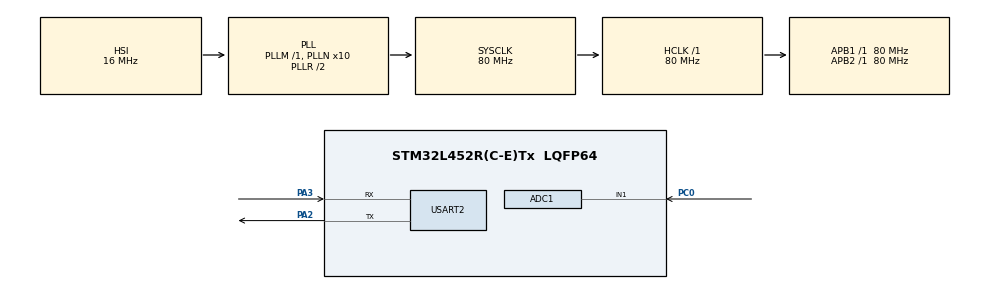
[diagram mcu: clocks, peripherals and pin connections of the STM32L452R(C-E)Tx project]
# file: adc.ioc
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ADC1.Channel-0\#ChannelRegularConversion=ADC_CHANNEL_1
ADC1.NbrOfConversionFlag=1
ADC1.OffsetNumber-0\#ChannelRegularConversion=ADC_OFFSET_NONE
ADC1.Rank-0\#ChannelRegularConversion=1
ADC1.SamplingTime-0\#ChannelRegularConversion=ADC_SAMPLETIME_2CYCLES_5
ADC1.master=1
Mcu.Family=STM32L4
Mcu.Name=STM32L452R(C-E)Tx
Mcu.Package=LQFP64
NVIC.PriorityGroup=NVIC_PRIORITYGROUP_4
PA2.Mode=Asynchronous
PA2.Signal=USART2_TX
PA3.Mode=Asynchronous
PA3.Signal=USART2_RX
PC0.Signal=ADCx_IN1
ProjectManager.HeapSize=0x200
ProjectManager.StackSize=0x400
ProjectManager.TargetToolchain=STM32CubeIDE
RCC.ADCFreq_Value=64000000
RCC.AHBFreq_Value=80000000
RCC.APB1Freq_Value=80000000
RCC.APB1TimFreq_Value=80000000
RCC.APB2Freq_Value=80000000
RCC.APB2TimFreq_Value=80000000
RCC.CortexFreq_Value=80000000
RCC.HCLKFreq_Value=80000000
RCC.HSE_VALUE=8000000
RCC.HSI48_VALUE=48000000
RCC.HSI_VALUE=16000000
RCC.MSI_VALUE=4000000
RCC.PLLN=10
RCC.PLLSourceVirtual=RCC_PLLSOURCE_HSI
RCC.PREFETCH_ENABLE=1
RCC.SYSCLKFreq_VALUE=80000000
RCC.SYSCLKSource=RCC_SYSCLKSOURCE_PLLCLK
RCC.USBFreq_Value=64000000
RCC.VCOOutputFreq_Value=160000000
SH.ADCx_IN1.0=ADC1_IN1,IN1-Single-Ended
USART2.VirtualMode-Asynchronous=VM_ASYNC
board=NUCLEO-L452RE

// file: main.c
/* USER CODE BEGIN Header */
/**
  ******************************************************************************
  * @file           : main.c
  * @brief          : Main program body
  ******************************************************************************
  * @attention
  *
  * Copyright (c) 2024 STMicroelectronics.
  * All rights reserved.
  *
  * This software is licensed under terms that can be found in the LICENSE file
  * in the root directory of this software component.
  * If no LICENSE file comes with this software, it is provided AS-IS.
  *
  ******************************************************************************
  */
/* USER CODE END Header */
#include "main.h"

ADC_HandleTypeDef hadc1;

UART_HandleTypeDef huart2;

void SystemClock_Config(void);
static void MX_GPIO_Init(void);
static void MX_ADC1_Init(void);
static void MX_USART2_UART_Init(void);

int main(void)
{

  /* MCU Configuration--------------------------------------------------------*/

  /* Reset of all peripherals, Initializes the Flash interface and the Systick. */
  HAL_Init();

  /* Configure the system clock */
  SystemClock_Config();

  /* Initialize all configured peripherals */
  MX_GPIO_Init();
  MX_ADC1_Init();
  MX_USART2_UART_Init();
  /* USER CODE BEGIN 2 */
  int lux;
  char *msg;
  /* USER CODE END 2 */

  /* Infinite loop */
  while (1)
  {

    /* USER CODE BEGIN 3 */
	  HAL_ADC_Start(&hadc1);
	  HAL_ADC_PollForConversion(&hadc1,20);
	  lux=HAL_ADC_GetValue(&hadc1);
	  sprintf(msg,"Light %hu\r\n", lux);
	  HAL_UART_Transmit(&huart2,(uint8_t*)msg,strlen(msg),HAL_MAX_DELAY);
	  HAL_Delay(500);
  }
  /* USER CODE END 3 */
}

void SystemClock_Config(void)
{
  RCC_OscInitTypeDef RCC_OscInitStruct = {0};
  RCC_ClkInitTypeDef RCC_ClkInitStruct = {0};

  /** Configure the main internal regulator output voltage
  */
  if (HAL_PWREx_ControlVoltageScaling(PWR_REGULATOR_VOLTAGE_SCALE1) != HAL_OK)
  {
    Error_Handler();
  }

  /** Initializes the RCC Oscillators according to the specified parameters
  * in the RCC_OscInitTypeDef structure.
  */
  RCC_OscInitStruct.OscillatorType = RCC_OSCILLATORTYPE_HSI;
  RCC_OscInitStruct.HSIState = RCC_HSI_ON;
  RCC_OscInitStruct.HSICalibrationValue = 64;
  RCC_OscInitStruct.PLL.PLLState = RCC_PLL_ON;
  RCC_OscInitStruct.PLL.PLLSource = RCC_PLLSOURCE_HSI;
  RCC_OscInitStruct.PLL.PLLM = 1;
  RCC_OscInitStruct.PLL.PLLN = 10;
  RCC_OscInitStruct.PLL.PLLP = RCC_PLLP_DIV7;
  RCC_OscInitStruct.PLL.PLLQ = RCC_PLLQ_DIV2;
  RCC_OscInitStruct.PLL.PLLR = RCC_PLLR_DIV2;
  if (HAL_RCC_OscConfig(&RCC_OscInitStruct) != HAL_OK)
  {
    Error_Handler();
  }

  /** Initializes the CPU, AHB and APB buses clocks
  */
  RCC_ClkInitStruct.ClockType = RCC_CLOCKTYPE_HCLK|RCC_CLOCKTYPE_SYSCLK
                              |RCC_CLOCKTYPE_PCLK1|RCC_CLOCKTYPE_PCLK2;
  RCC_ClkInitStruct.SYSCLKSource = RCC_SYSCLKSOURCE_PLLCLK;
  RCC_ClkInitStruct.AHBCLKDivider = RCC_SYSCLK_DIV1;
  RCC_ClkInitStruct.APB1CLKDivider = RCC_HCLK_DIV1;
  RCC_ClkInitStruct.APB2CLKDivider = RCC_HCLK_DIV1;

  if (HAL_RCC_ClockConfig(&RCC_ClkInitStruct, FLASH_LATENCY_4) != HAL_OK)
  {
    Error_Handler();
  }
}

static void MX_ADC1_Init(void)
{

  ADC_ChannelConfTypeDef sConfig = {0};

  /** Common config
  */
  hadc1.Instance = ADC1;
  hadc1.Init.ClockPrescaler = ADC_CLOCK_ASYNC_DIV1;
  hadc1.Init.Resolution = ADC_RESOLUTION_12B;
  hadc1.Init.DataAlign = ADC_DATAALIGN_RIGHT;
  hadc1.Init.ScanConvMode = ADC_SCAN_DISABLE;
  hadc1.Init.EOCSelection = ADC_EOC_SINGLE_CONV;
  hadc1.Init.LowPowerAutoWait = DISABLE;
  hadc1.Init.ContinuousConvMode = DISABLE;
  hadc1.Init.NbrOfConversion = 1;
  hadc1.Init.DiscontinuousConvMode = DISABLE;
  hadc1.Init.ExternalTrigConv = ADC_SOFTWARE_START;
  hadc1.Init.ExternalTrigConvEdge = ADC_EXTERNALTRIGCONVEDGE_NONE;
  hadc1.Init.DMAContinuousRequests = DISABLE;
  hadc1.Init.Overrun = ADC_OVR_DATA_PRESERVED;
  hadc1.Init.OversamplingMode = DISABLE;
  if (HAL_ADC_Init(&hadc1) != HAL_OK)
  {
    Error_Handler();
  }

  /** Configure Regular Channel
  */
  sConfig.Channel = ADC_CHANNEL_1;
  sConfig.Rank = ADC_REGULAR_RANK_1;
  sConfig.SamplingTime = ADC_SAMPLETIME_2CYCLES_5;
  sConfig.SingleDiff = ADC_SINGLE_ENDED;
  sConfig.OffsetNumber = ADC_OFFSET_NONE;
  sConfig.Offset = 0;
  if (HAL_ADC_ConfigChannel(&hadc1, &sConfig) != HAL_OK)
  {
    Error_Handler();
  }

}

static void MX_USART2_UART_Init(void)
{

  huart2.Instance = USART2;
  huart2.Init.BaudRate = 115200;
  huart2.Init.WordLength = UART_WORDLENGTH_8B;
  huart2.Init.StopBits = UART_STOPBITS_1;
  huart2.Init.Parity = UART_PARITY_NONE;
  huart2.Init.Mode = UART_MODE_TX_RX;
  huart2.Init.HwFlowCtl = UART_HWCONTROL_NONE;
  huart2.Init.OverSampling = UART_OVERSAMPLING_16;
  huart2.Init.OneBitSampling = UART_ONE_BIT_SAMPLE_DISABLE;
  huart2.AdvancedInit.AdvFeatureInit = UART_ADVFEATURE_NO_INIT;
  if (HAL_UART_Init(&huart2) != HAL_OK)
  {
    Error_Handler();
  }

}

static void MX_GPIO_Init(void)
{

  /* GPIO Ports Clock Enable */
  __HAL_RCC_GPIOC_CLK_ENABLE();
  __HAL_RCC_GPIOA_CLK_ENABLE();

}

void Error_Handler(void)
{
  __disable_irq();
  while (1)
  {
  }
}
